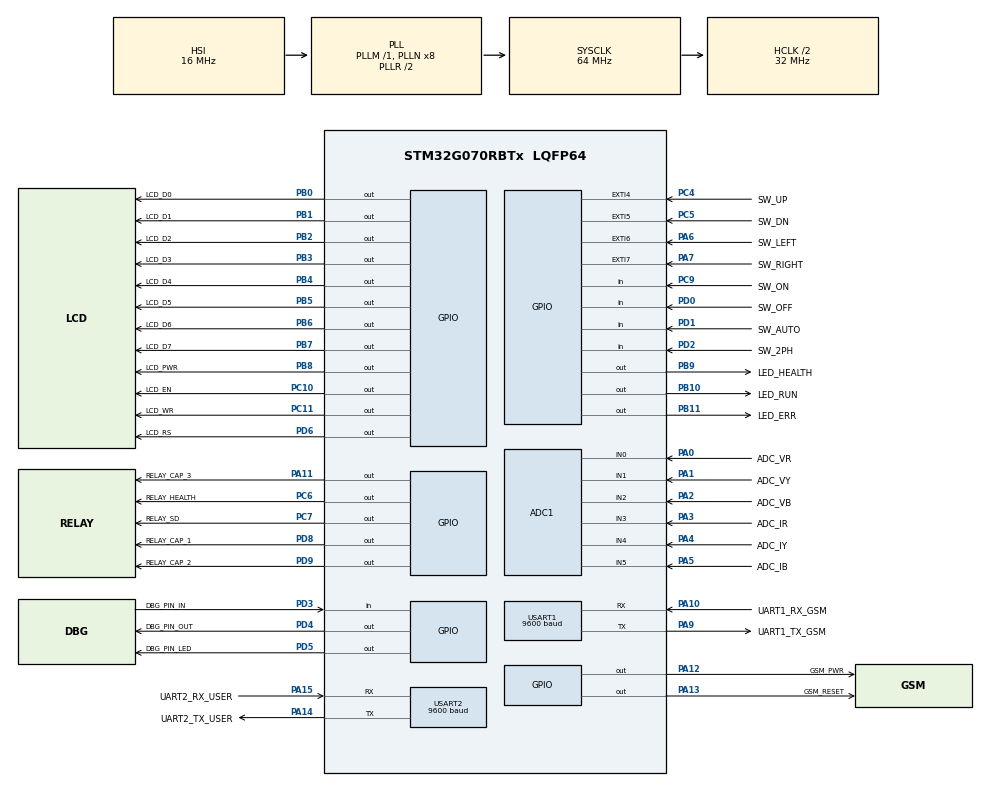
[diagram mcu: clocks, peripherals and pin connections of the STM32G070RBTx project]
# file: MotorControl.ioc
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ADC1.Channel-0\#ChannelRegularConversion=ADC_CHANNEL_0
ADC1.NbrOfConversionFlag=1
ADC1.Rank-0\#ChannelRegularConversion=1
ADC1.SamplingTime-0\#ChannelRegularConversion=ADC_SAMPLINGTIME_COMMON_1
ADC1.SelectedChannel=ADC_CHANNEL_0|ADC_CHANNEL_1|ADC_CHANNEL_2|ADC_CHANNEL_3|ADC_CHANNEL_4|ADC_CHANNEL_5
ADC1.master=1
Mcu.Family=STM32G0
Mcu.Name=STM32G070RBTx
Mcu.Package=LQFP64
PA0.GPIO_Label=ADC_VR
PA0.Mode=IN0
PA0.Signal=ADC1_IN0
PA1.GPIO_Label=ADC_VY
PA1.Mode=IN1
PA1.Signal=ADC1_IN1
PA10.GPIO_Label=UART1_RX_GSM
PA10.Mode=Asynchronous
PA10.Signal=USART1_RX
PA11\ [PA9].GPIO_Label=RELAY_CAP_3
PA11\ [PA9].Signal=GPIO_Output
PA12\ [PA10].GPIO_Label=GSM_PWR
PA12\ [PA10].Signal=GPIO_Output
PA13.GPIO_Label=GSM_RESET
PA13.Signal=GPIO_Output
PA14-BOOT0.GPIO_Label=UART2_TX_USER
PA14-BOOT0.Mode=Asynchronous
PA14-BOOT0.Signal=USART2_TX
PA15.GPIO_Label=UART2_RX_USER
PA15.Mode=Asynchronous
PA15.Signal=USART2_RX
PA2.GPIO_Label=ADC_VB
PA2.Mode=IN2
PA2.Signal=ADC1_IN2
PA3.GPIO_Label=ADC_IR
PA3.Mode=IN3
PA3.Signal=ADC1_IN3
PA4.GPIO_Label=ADC_IY
PA4.Mode=IN4
PA4.Signal=ADC1_IN4
PA5.GPIO_Label=ADC_IB
PA5.Mode=IN5
PA5.Signal=ADC1_IN5
PA6.GPIO_Label=SW_LEFT
PA6.Signal=GPXTI6
PA7.GPIO_Label=SW_RIGHT
PA7.Signal=GPXTI7
PA9.GPIO_Label=UART1_TX_GSM
PA9.Mode=Asynchronous
PA9.Signal=USART1_TX
PB0.GPIO_Label=LCD_D0
PB0.Signal=GPIO_Output
PB1.GPIO_Label=LCD_D1
PB1.Signal=GPIO_Output
PB10.GPIO_Label=LED_RUN
PB10.Signal=GPIO_Output
PB11.GPIO_Label=LED_ERR
PB11.Signal=GPIO_Output
PB2.GPIO_Label=LCD_D2
PB2.Signal=GPIO_Output
PB3.GPIO_Label=LCD_D3
PB3.Signal=GPIO_Output
PB4.GPIO_Label=LCD_D4
PB4.Signal=GPIO_Output
PB5.GPIO_Label=LCD_D5
PB5.Signal=GPIO_Output
PB6.GPIO_Label=LCD_D6
PB6.Signal=GPIO_Output
PB7.GPIO_Label=LCD_D7
PB7.Signal=GPIO_Output
PB8.GPIO_Label=LCD_PWR
PB8.Signal=GPIO_Output
PB9.GPIO_Label=LED_HEALTH
PB9.Signal=GPIO_Output
PC10.GPIO_Label=LCD_EN
PC10.Signal=GPIO_Output
PC11.GPIO_Label=LCD_WR
PC11.Signal=GPIO_Output
PC4.GPIO_Label=SW_UP
PC4.Signal=GPXTI4
PC5.GPIO_Label=SW_DN
PC5.Signal=GPXTI5
PC6.GPIO_Label=RELAY_HEALTH
PC6.Signal=GPIO_Output
PC7.GPIO_Label=RELAY_SD
PC7.Signal=GPIO_Output
PC9.GPIO_Label=SW_ON
PC9.Signal=GPIO_Input
PD0.GPIO_Label=SW_OFF
PD0.Signal=GPIO_Input
PD1.GPIO_Label=SW_AUTO
PD1.Signal=GPIO_Input
PD2.GPIO_Label=SW_2PH
PD2.Signal=GPIO_Input
PD3.GPIO_Label=DBG_PIN_IN
PD3.Signal=GPIO_Input
PD4.GPIO_Label=DBG_PIN_OUT
PD4.Signal=GPIO_Output
PD5.GPIO_Label=DBG_PIN_LED
PD5.Signal=GPIO_Output
PD6.GPIO_Label=LCD_RS
PD6.Signal=GPIO_Output
PD8.GPIO_Label=RELAY_CAP_1
PD8.Signal=GPIO_Output
PD9.GPIO_Label=RELAY_CAP_2
PD9.Signal=GPIO_Output
ProjectManager.HeapSize=0x200
ProjectManager.StackSize=0x400
ProjectManager.TargetToolchain=STM32CubeIDE
RCC.ADCFreq_Value=64000000
RCC.AHBCLKDivider=RCC_SYSCLK_DIV2
RCC.AHBFreq_Value=32000000
RCC.CortexFreq_Value=32000000
RCC.EXTERNAL_CLOCK_VALUE=48000
RCC.HCLKFreq_Value=32000000
RCC.HSE_VALUE=8000000
RCC.HSI_VALUE=16000000
RCC.LSE_VALUE=32768
RCC.SYSCLKFreq_VALUE=64000000
RCC.SYSCLKSource=RCC_SYSCLKSOURCE_PLLCLK
RCC.VCOOutputFreq_Value=128000000
USART1.BaudRate=9600
USART1.VirtualMode-Asynchronous=VM_ASYNC
USART2.BaudRate=9600
USART2.VirtualMode-Asynchronous=VM_ASYNC
board=custom

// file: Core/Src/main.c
/* USER CODE BEGIN Header */
/**
  ******************************************************************************
  * @file           : main.c
  * @brief          : Main program body
  ******************************************************************************
  * @attention
  *
  * Copyright (c) 2025 STMicroelectronics.
  * All rights reserved.
  *
  * This software is licensed under terms that can be found in the LICENSE file
  * in the root directory of this software component.
  * If no LICENSE file comes with this software, it is provided AS-IS.
  *
  ******************************************************************************
  */
/* USER CODE END Header */
#include "main.h"

/* USER CODE BEGIN Includes */
#include "aw_host.h"
#include "aw_typedef.h"
#include "aw_config_app.h"
#include "aw_config_io.h"
/* USER CODE END Includes */

ADC_HandleTypeDef hadc1;

UART_HandleTypeDef huart1;
UART_HandleTypeDef huart2;

void SystemClock_Config(void);
static void MX_GPIO_Init(void);
static void MX_ADC1_Init(void);
static void MX_USART1_UART_Init(void);
static void MX_USART2_UART_Init(void);

int main(void)
{

  /* MCU Configuration--------------------------------------------------------*/

  /* Reset of all peripherals, Initializes the Flash interface and the Systick. */
  HAL_Init();

  /* Configure the system clock */
  SystemClock_Config();

  /* Initialize all configured peripherals */
  MX_GPIO_Init();
  MX_ADC1_Init();
  MX_USART1_UART_Init();
  MX_USART2_UART_Init();

  /* Infinite loop */
  /* USER CODE BEGIN WHILE */
  while (1)
  {
	  kt_hostProcess();
    /* USER CODE END WHILE */

  }
}

void SystemClock_Config(void)
{
  RCC_OscInitTypeDef RCC_OscInitStruct = {0};
  RCC_ClkInitTypeDef RCC_ClkInitStruct = {0};

  /** Configure the main internal regulator output voltage
  */
  HAL_PWREx_ControlVoltageScaling(PWR_REGULATOR_VOLTAGE_SCALE1);

  /** Initializes the RCC Oscillators according to the specified parameters
  * in the RCC_OscInitTypeDef structure.
  */
  RCC_OscInitStruct.OscillatorType = RCC_OSCILLATORTYPE_HSI;
  RCC_OscInitStruct.HSIState = RCC_HSI_ON;
  RCC_OscInitStruct.HSIDiv = RCC_HSI_DIV1;
  RCC_OscInitStruct.HSICalibrationValue = RCC_HSICALIBRATION_DEFAULT;
  RCC_OscInitStruct.PLL.PLLState = RCC_PLL_ON;
  RCC_OscInitStruct.PLL.PLLSource = RCC_PLLSOURCE_HSI;
  RCC_OscInitStruct.PLL.PLLM = RCC_PLLM_DIV1;
  RCC_OscInitStruct.PLL.PLLN = 8;
  RCC_OscInitStruct.PLL.PLLP = RCC_PLLP_DIV2;
  RCC_OscInitStruct.PLL.PLLR = RCC_PLLR_DIV2;
  if (HAL_RCC_OscConfig(&RCC_OscInitStruct) != HAL_OK)
  {
    Error_Handler();
  }

  /** Initializes the CPU, AHB and APB buses clocks
  */
  RCC_ClkInitStruct.ClockType = RCC_CLOCKTYPE_HCLK|RCC_CLOCKTYPE_SYSCLK
                              |RCC_CLOCKTYPE_PCLK1;
  RCC_ClkInitStruct.SYSCLKSource = RCC_SYSCLKSOURCE_PLLCLK;
  RCC_ClkInitStruct.AHBCLKDivider = RCC_SYSCLK_DIV2;
  RCC_ClkInitStruct.APB1CLKDivider = RCC_HCLK_DIV1;

  if (HAL_RCC_ClockConfig(&RCC_ClkInitStruct, FLASH_LATENCY_1) != HAL_OK)
  {
    Error_Handler();
  }
}

static void MX_ADC1_Init(void)
{

  ADC_ChannelConfTypeDef sConfig = {0};

  /** Configure the global features of the ADC (Clock, Resolution, Data Alignment and number of conversion)
  */
  hadc1.Instance = ADC1;
  hadc1.Init.ClockPrescaler = ADC_CLOCK_SYNC_PCLK_DIV1;
  hadc1.Init.Resolution = ADC_RESOLUTION_12B;
  hadc1.Init.DataAlign = ADC_DATAALIGN_RIGHT;
  hadc1.Init.ScanConvMode = ADC_SCAN_DISABLE;
  hadc1.Init.EOCSelection = ADC_EOC_SINGLE_CONV;
  hadc1.Init.LowPowerAutoWait = DISABLE;
  hadc1.Init.LowPowerAutoPowerOff = DISABLE;
  hadc1.Init.ContinuousConvMode = DISABLE;
  hadc1.Init.NbrOfConversion = 1;
  hadc1.Init.DiscontinuousConvMode = DISABLE;
  hadc1.Init.ExternalTrigConv = ADC_SOFTWARE_START;
  hadc1.Init.ExternalTrigConvEdge = ADC_EXTERNALTRIGCONVEDGE_NONE;
  hadc1.Init.DMAContinuousRequests = DISABLE;
  hadc1.Init.Overrun = ADC_OVR_DATA_PRESERVED;
  hadc1.Init.SamplingTimeCommon1 = ADC_SAMPLETIME_1CYCLE_5;
  hadc1.Init.SamplingTimeCommon2 = ADC_SAMPLETIME_1CYCLE_5;
  hadc1.Init.OversamplingMode = DISABLE;
  hadc1.Init.TriggerFrequencyMode = ADC_TRIGGER_FREQ_HIGH;
  if (HAL_ADC_Init(&hadc1) != HAL_OK)
  {
    Error_Handler();
  }

  /** Configure Regular Channel
  */
  sConfig.Channel = ADC_CHANNEL_0;
  sConfig.Rank = ADC_REGULAR_RANK_1;
  sConfig.SamplingTime = ADC_SAMPLINGTIME_COMMON_1;
  if (HAL_ADC_ConfigChannel(&hadc1, &sConfig) != HAL_OK)
  {
    Error_Handler();
  }

}

static void MX_USART1_UART_Init(void)
{

  huart1.Instance = USART1;
  huart1.Init.BaudRate = 9600;
  huart1.Init.WordLength = UART_WORDLENGTH_8B;
  huart1.Init.StopBits = UART_STOPBITS_1;
  huart1.Init.Parity = UART_PARITY_NONE;
  huart1.Init.Mode = UART_MODE_TX_RX;
  huart1.Init.HwFlowCtl = UART_HWCONTROL_NONE;
  huart1.Init.OverSampling = UART_OVERSAMPLING_16;
  huart1.Init.OneBitSampling = UART_ONE_BIT_SAMPLE_DISABLE;
  huart1.Init.ClockPrescaler = UART_PRESCALER_DIV1;
  huart1.AdvancedInit.AdvFeatureInit = UART_ADVFEATURE_NO_INIT;
  if (HAL_UART_Init(&huart1) != HAL_OK)
  {
    Error_Handler();
  }
  if (HAL_UARTEx_SetTxFifoThreshold(&huart1, UART_TXFIFO_THRESHOLD_1_8) != HAL_OK)
  {
    Error_Handler();
  }
  if (HAL_UARTEx_SetRxFifoThreshold(&huart1, UART_RXFIFO_THRESHOLD_1_8) != HAL_OK)
  {
    Error_Handler();
  }
  if (HAL_UARTEx_DisableFifoMode(&huart1) != HAL_OK)
  {
    Error_Handler();
  }

}

static void MX_USART2_UART_Init(void)
{

  huart2.Instance = USART2;
  huart2.Init.BaudRate = 9600;
  huart2.Init.WordLength = UART_WORDLENGTH_8B;
  huart2.Init.StopBits = UART_STOPBITS_1;
  huart2.Init.Parity = UART_PARITY_NONE;
  huart2.Init.Mode = UART_MODE_TX_RX;
  huart2.Init.HwFlowCtl = UART_HWCONTROL_NONE;
  huart2.Init.OverSampling = UART_OVERSAMPLING_16;
  huart2.Init.OneBitSampling = UART_ONE_BIT_SAMPLE_DISABLE;
  huart2.Init.ClockPrescaler = UART_PRESCALER_DIV1;
  huart2.AdvancedInit.AdvFeatureInit = UART_ADVFEATURE_NO_INIT;
  if (HAL_UART_Init(&huart2) != HAL_OK)
  {
    Error_Handler();
  }
  if (HAL_UARTEx_SetTxFifoThreshold(&huart2, UART_TXFIFO_THRESHOLD_1_8) != HAL_OK)
  {
    Error_Handler();
  }
  if (HAL_UARTEx_SetRxFifoThreshold(&huart2, UART_RXFIFO_THRESHOLD_1_8) != HAL_OK)
  {
    Error_Handler();
  }
  if (HAL_UARTEx_DisableFifoMode(&huart2) != HAL_OK)
  {
    Error_Handler();
  }

}

static void MX_GPIO_Init(void)
{
  GPIO_InitTypeDef GPIO_InitStruct = {0};

  /* GPIO Ports Clock Enable */
  __HAL_RCC_GPIOC_CLK_ENABLE();
  __HAL_RCC_GPIOA_CLK_ENABLE();
  __HAL_RCC_GPIOB_CLK_ENABLE();
  __HAL_RCC_GPIOD_CLK_ENABLE();

  /*Configure GPIO pin Output Level */
  HAL_GPIO_WritePin(GPIOC, LCD_WR_Pin|RELAY_HEALTH_Pin|RELAY_SD_Pin|LCD_EN_Pin, GPIO_PIN_RESET);

  /*Configure GPIO pin Output Level */
  HAL_GPIO_WritePin(GPIOB, LCD_D0_Pin|LCD_D1_Pin|LCD_D2_Pin|LED_RUN_Pin
                          |LED_ERR_Pin|LCD_D3_Pin|LCD_D4_Pin|LCD_D5_Pin
                          |LCD_D6_Pin|LCD_D7_Pin|LCD_PWR_Pin|LED_HEALTH_Pin, GPIO_PIN_RESET);

  /*Configure GPIO pin Output Level */
  HAL_GPIO_WritePin(GPIOD, RELAY_CAP_1_Pin|RELAY_CAP_2_Pin|DBG_PIN_OUT_Pin|DBG_PIN_LED_Pin
                          |LCD_RS_Pin, GPIO_PIN_RESET);

  /*Configure GPIO pin Output Level */
  HAL_GPIO_WritePin(GPIOA, RELAY_CAP_3_Pin|GSM_PWR_Pin|GSM_RESET_Pin, GPIO_PIN_RESET);

  /*Configure GPIO pins : LCD_WR_Pin RELAY_HEALTH_Pin RELAY_SD_Pin LCD_EN_Pin */
  GPIO_InitStruct.Pin = LCD_WR_Pin|RELAY_HEALTH_Pin|RELAY_SD_Pin|LCD_EN_Pin;
  GPIO_InitStruct.Mode = GPIO_MODE_OUTPUT_PP;
  GPIO_InitStruct.Pull = GPIO_NOPULL;
  GPIO_InitStruct.Speed = GPIO_SPEED_FREQ_LOW;
  HAL_GPIO_Init(GPIOC, &GPIO_InitStruct);

  /*Configure GPIO pins : SW_LEFT_Pin SW_RIGHT_Pin */
  GPIO_InitStruct.Pin = SW_LEFT_Pin|SW_RIGHT_Pin;
  GPIO_InitStruct.Mode = GPIO_MODE_IT_RISING;
  GPIO_InitStruct.Pull = GPIO_NOPULL;
  HAL_GPIO_Init(GPIOA, &GPIO_InitStruct);

  /*Configure GPIO pins : SW_UP_Pin SW_DN_Pin */
  GPIO_InitStruct.Pin = SW_UP_Pin|SW_DN_Pin;
  GPIO_InitStruct.Mode = GPIO_MODE_IT_RISING;
  GPIO_InitStruct.Pull = GPIO_NOPULL;
  HAL_GPIO_Init(GPIOC, &GPIO_InitStruct);

  /*Configure GPIO pins : LCD_D0_Pin LCD_D1_Pin LCD_D2_Pin LED_RUN_Pin
                           LED_ERR_Pin LCD_D3_Pin LCD_D4_Pin LCD_D5_Pin
                           LCD_D6_Pin LCD_D7_Pin LCD_PWR_Pin LED_HEALTH_Pin */
  GPIO_InitStruct.Pin = LCD_D0_Pin|LCD_D1_Pin|LCD_D2_Pin|LED_RUN_Pin
                          |LED_ERR_Pin|LCD_D3_Pin|LCD_D4_Pin|LCD_D5_Pin
                          |LCD_D6_Pin|LCD_D7_Pin|LCD_PWR_Pin|LED_HEALTH_Pin;
  GPIO_InitStruct.Mode = GPIO_MODE_OUTPUT_PP;
  GPIO_InitStruct.Pull = GPIO_NOPULL;
  GPIO_InitStruct.Speed = GPIO_SPEED_FREQ_LOW;
  HAL_GPIO_Init(GPIOB, &GPIO_InitStruct);

  /*Configure GPIO pins : RELAY_CAP_1_Pin RELAY_CAP_2_Pin DBG_PIN_OUT_Pin DBG_PIN_LED_Pin
                           LCD_RS_Pin */
  GPIO_InitStruct.Pin = RELAY_CAP_1_Pin|RELAY_CAP_2_Pin|DBG_PIN_OUT_Pin|DBG_PIN_LED_Pin
                          |LCD_RS_Pin;
  GPIO_InitStruct.Mode = GPIO_MODE_OUTPUT_PP;
  GPIO_InitStruct.Pull = GPIO_NOPULL;
  GPIO_InitStruct.Speed = GPIO_SPEED_FREQ_LOW;
  HAL_GPIO_Init(GPIOD, &GPIO_InitStruct);

  /*Configure GPIO pins : RELAY_CAP_3_Pin GSM_PWR_Pin GSM_RESET_Pin */
  GPIO_InitStruct.Pin = RELAY_CAP_3_Pin|GSM_PWR_Pin|GSM_RESET_Pin;
  GPIO_InitStruct.Mode = GPIO_MODE_OUTPUT_PP;
  GPIO_InitStruct.Pull = GPIO_NOPULL;
  GPIO_InitStruct.Speed = GPIO_SPEED_FREQ_LOW;
  HAL_GPIO_Init(GPIOA, &GPIO_InitStruct);

  /*Configure GPIO pin : SW_ON_Pin */
  GPIO_InitStruct.Pin = SW_ON_Pin;
  GPIO_InitStruct.Mode = GPIO_MODE_INPUT;
  GPIO_InitStruct.Pull = GPIO_NOPULL;
  HAL_GPIO_Init(SW_ON_GPIO_Port, &GPIO_InitStruct);

  /*Configure GPIO pins : SW_OFF_Pin SW_AUTO_Pin SW_2PH_Pin DBG_PIN_IN_Pin */
  GPIO_InitStruct.Pin = SW_OFF_Pin|SW_AUTO_Pin|SW_2PH_Pin|DBG_PIN_IN_Pin;
  GPIO_InitStruct.Mode = GPIO_MODE_INPUT;
  GPIO_InitStruct.Pull = GPIO_NOPULL;
  HAL_GPIO_Init(GPIOD, &GPIO_InitStruct);

}

void Error_Handler(void)
{
  __disable_irq();
  while (1)
  {
  }
}
